# EFM32GG990F1024 register map
File version: 1.6
Registers are 32-bit, read-write, reset 0x0 unless marked. A register's access mark holds for its fields unless they carry their own. Offsets are from the block's base; [hi:lo] are bit positions; {n}, {i} and the like mark numbered series.

## VCMP
Base 0x40000000
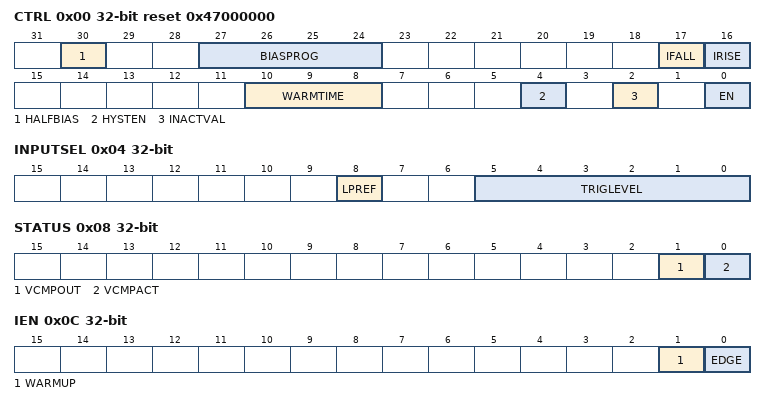
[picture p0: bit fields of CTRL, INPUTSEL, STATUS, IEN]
0x00 CTRL reset 0x47000000 — Control Register
  [30] HALFBIAS — Half Bias Current
  [27:24] BIASPROG — VCMP Bias Programming Value
  [17] IFALL — Falling Edge Interrupt Sense
  [16] IRISE — Rising Edge Interrupt Sense
  [10:8] WARMTIME — Warm-Up Time
    0=4CYCLES (4 HFPERCLK cycles); 1=8CYCLES (8 HFPERCLK cycles); 2=16CYCLES (16 HFPERCLK cycles); 3=32CYCLES (32 HFPERCLK cycles); 4=64CYCLES (64 HFPERCLK cycles); 5=128CYCLES (128 HFPERCLK cycles); 6=256CYCLES (256 HFPERCLK cycles); 7=512CYCLES (512 HFPERCLK cycles)
  [4] HYSTEN — Hysteresis Enable
  [2] INACTVAL — Inactive Value
  [0] EN — Voltage Supply Comparator Enable
0x04 INPUTSEL — Input Selection Register
  [8] LPREF — Low Power Reference
  [5:0] TRIGLEVEL — Trigger Level
0x08 STATUS ro
  [1] VCMPOUT — Voltage Supply Comparator Output
  [0] VCMPACT — Voltage Supply Comparator Active
0x0C IEN — Interrupt Enable Register
  [1] WARMUP — Warm-up Interrupt Enable
  [0] EDGE — Edge Trigger Interrupt Enable
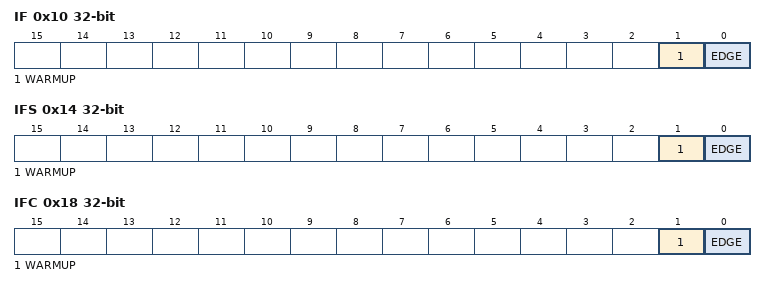
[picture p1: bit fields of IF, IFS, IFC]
0x10 IF ro — Interrupt Flag Register
  [1] WARMUP — Warm-up Interrupt Flag
  [0] EDGE — Edge Triggered Interrupt Flag
0x14 IFS wo — Interrupt Flag Set Register
  [1] WARMUP — Warm-up Interrupt Flag Set
  [0] EDGE — Edge Triggered Interrupt Flag Set
0x18 IFC wo — Interrupt Flag Clear Register
  [1] WARMUP — Warm-up Interrupt Flag Clear
  [0] EDGE — Edge Triggered Interrupt Flag Clear

## LCD
Base 0x4008A000
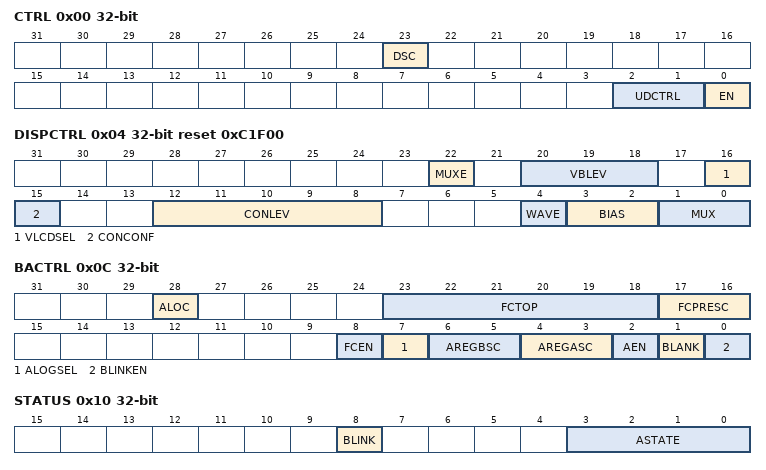
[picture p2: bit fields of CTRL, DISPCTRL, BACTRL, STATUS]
0x00 CTRL — Control Register
  [23] DSC — Direct Segment Control
  [2:1] UDCTRL — Update Data Control
    0=REGULAR (The data transfer is controlled by SW. Transfer is performed as soon as possible); 1=FCEVENT (The data transfer is done at the next event triggered by the Frame Counter); 2=FRAMESTART (The data transfer is done continously at every LCD frame start)
  [0] EN — LCD Enable
0x04 DISPCTRL reset 0xC1F00 — Display Control Register
  [22] MUXE — Extended Mux Configuration
  [20:18] VBLEV — Voltage Boost Level
    0=LEVEL0 (Minimum boost level); {v}=LEVEL{v} (v=1..6); 7=LEVEL7 (Maximum boost level)
  [16] VLCDSEL — VLCD Selection
  [15] CONCONF — Contrast Configuration
  [12:8] CONLEV — Contrast Level
    0=MIN (Minimum contrast); 31=MAX (Maximum contrast)
  [4] WAVE — Waveform Selection
  [3:2] BIAS — Bias Configuration
    0=STATIC; 1=ONEHALF (1/2 Bias); 2=ONETHIRD (1/3 Bias); 3=ONEFOURTH (1/4 Bias)
  [1:0] MUX — Mux Configuration
    0=STATIC; 1=DUPLEX; 2=TRIPLEX; 3=QUADRUPLEX
0x08 SEGEN — Segment Enable Register
  [9:0] SEGEN — Segment Enable
0x0C BACTRL — Blink and Animation Control Register
  [28] ALOC — Animation Location
  [23:18] FCTOP — Frame Counter Top Value
  [17:16] FCPRESC — Frame Counter Prescaler
    0=DIV1 (CLKFC = CLKFRAME / 1); 1=DIV2 (CLKFC = CLKFRAME / 2); 2=DIV4 (CLKFC = CLKFRAME / 4); 3=DIV8 (CLKFC = CLKFRAME / 8)
  [8] FCEN — Frame Counter Enable
  [7] ALOGSEL — Animate Logic Function Select
  [6:5] AREGBSC — Animate Register B Shift Control
    0=NOSHIFT (No Shift operation on Animation Register B); 1=SHIFTLEFT (Animation Register B is shifted left); 2=SHIFTRIGHT (Animation Register B is shifted right)
  [4:3] AREGASC — Animate Register A Shift Control
    0=NOSHIFT (No Shift operation on Animation Register A); 1=SHIFTLEFT (Animation Register A is shifted left); 2=SHIFTRIGHT (Animation Register A is shifted right)
  [2] AEN — Animation Enable
  [1] BLANK — Blank Display
  [0] BLINKEN — Blink Enable
0x10 STATUS ro
  [8] BLINK — Blink State
  [3:0] ASTATE — Current Animation State
0x14 AREGA — Animation Register A
  [7:0] AREGA — Animation Register A Data
0x18 AREGB — Animation Register B
  [7:0] AREGB — Animation Register B Data
0x1C IF ro — Interrupt Flag Register
  [0] FC — Frame Counter Interrupt Flag
0x20 IFS wo — Interrupt Flag Set Register
  [0] FC — Frame Counter Interrupt Flag Set
0x24 IFC wo — Interrupt Flag Clear Register
  [0] FC — Frame Counter Interrupt Flag Clear
0x28 IEN — Interrupt Enable Register
  [0] FC — Frame Counter Interrupt Enable
{0x40+4i} SEGD{i}L (i=0..3) — Segment Data Low Register {i}
  [31:0] SEGD{i}L — COM{i} Segment Data Low
{0x50+4i} SEGD{i}H (i=0..3) — Segment Data High Register {i}
  [7:0] SEGD{i}H — COM{i} Segment Data High
0x60 FREEZE
  [0] REGFREEZE — Register Update Freeze
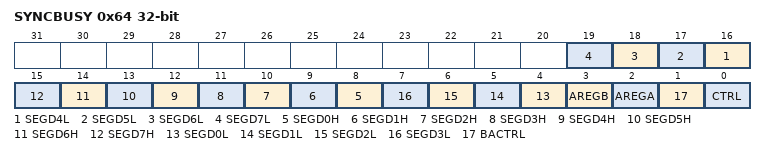
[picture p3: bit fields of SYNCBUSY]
0x64 SYNCBUSY ro — Synchronization Busy Register
  [n+12] SEGD{n}L (n=4..7) — LCD_SEGD{n}L Register Busy
  [n+8] SEGD{n}H (n=0..7) — LCD_SEGD{n}H Register Busy
  [n+4] SEGD{n}L (n=0..3) — LCD_SEGD{n}L Register Busy
  [3] AREGB — LCD_AREGB Register Busy
  [2] AREGA — LCD_AREGA Register Busy
  [1] BACTRL — LCD_BACTRL Register Busy
  [0] CTRL — LCD_CTRL Register Busy
{0xA4+4i} SEGD{i}H (i=4..7) — Segment Data High Register {i}
  [7:0] SEGD{i}H — COM{i-4} Segment Data High
{0xBC+4i} SEGD{i}L (i=4..7) — Segment Data Low Register {i}
  [31:0] SEGD{i}L — COM{i} Segment Data

## RTC
Base 0x40080000
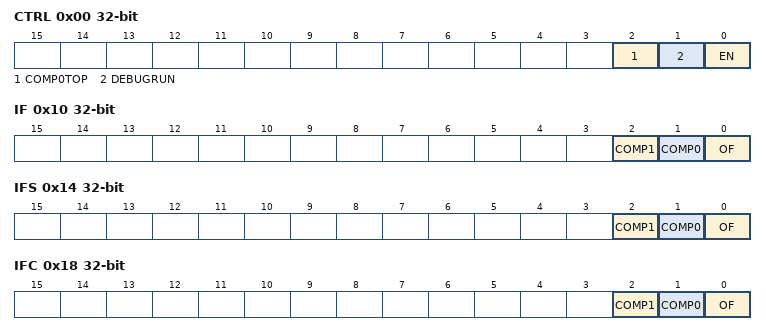
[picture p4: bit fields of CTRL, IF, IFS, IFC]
0x00 CTRL — Control Register
  [2] COMP0TOP — Compare Channel 0 is Top Value
  [1] DEBUGRUN — Debug Mode Run Enable
  [0] EN — RTC Enable
0x04 CNT — Counter Value Register
  [23:0] CNT — Counter Value
0x08 COMP0 — Compare Value Register 0
  [23:0] COMP0 — Compare Value 0
0x0C COMP1 — Compare Value Register 1
  [23:0] COMP1 — Compare Value 1
0x10 IF ro — Interrupt Flag Register
  [2] COMP1 — Compare Match 1 Interrupt Flag
  [1] COMP0 — Compare Match 0 Interrupt Flag
  [0] OF — Overflow Interrupt Flag
0x14 IFS wo — Interrupt Flag Set Register
  [2] COMP1 — Set Compare match 1 Interrupt Flag
  [1] COMP0 — Set Compare match 0 Interrupt Flag
  [0] OF — Set Overflow Interrupt Flag
0x18 IFC wo — Interrupt Flag Clear Register
  [2] COMP1 — Clear Compare match 1 Interrupt Flag
  [1] COMP0 — Clear Compare match 0 Interrupt Flag
  [0] OF — Clear Overflow Interrupt Flag
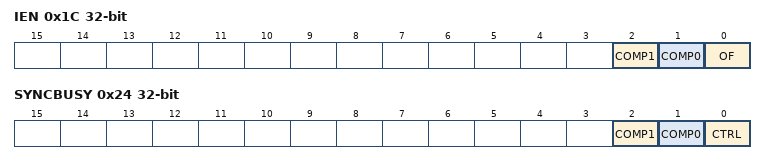
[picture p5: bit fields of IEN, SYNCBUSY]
0x1C IEN — Interrupt Enable Register
  [2] COMP1 — Compare Match 1 Interrupt Enable
  [1] COMP0 — Compare Match 0 Interrupt Enable
  [0] OF — Overflow Interrupt Enable
0x20 FREEZE
  [0] REGFREEZE — Register Update Freeze
0x24 SYNCBUSY ro — Synchronization Busy Register
  [2] COMP1 — RTC_COMP1 Register Busy
  [1] COMP0 — RTC_COMP0 Register Busy
  [0] CTRL — RTC_CTRL Register Busy

## WDOG
Base 0x40088000
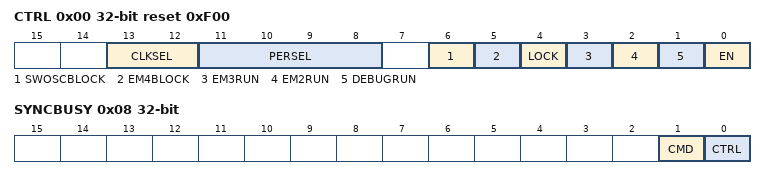
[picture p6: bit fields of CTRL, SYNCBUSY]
0x00 CTRL reset 0xF00 — Control Register
  [13:12] CLKSEL — Watchdog Clock Select
    0=ULFRCO; 1=LFRCO; 2=LFXO
  [11:8] PERSEL — Watchdog Timeout Period Select.
  [6] SWOSCBLOCK — Software Oscillator Disable Block
  [5] EM4BLOCK — Energy Mode 4 Block
  [4] LOCK — Configuration lock
  [3] EM3RUN — Energy Mode 3 Run Enable
  [2] EM2RUN — Energy Mode 2 Run Enable
  [1] DEBUGRUN — Debug Mode Run Enable
  [0] EN — Watchdog Timer Enable
0x04 CMD wo — Command Register
  [0] CLEAR — Watchdog Timer Clear
0x08 SYNCBUSY ro — Synchronization Busy Register
  [1] CMD — WDOG_CMD Register Busy
  [0] CTRL — WDOG_CTRL Register Busy
